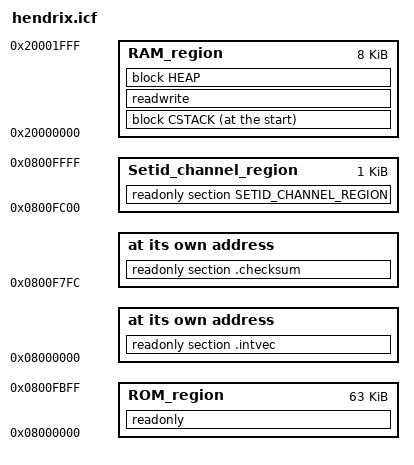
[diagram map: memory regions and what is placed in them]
/*###ICF### Section handled by ICF editor, don't touch! ****/
/*-Editor annotation file-*/
/* IcfEditorFile="$TOOLKIT_DIR$\config\ide\IcfEditor\cortex_v1_0.xml" */
/*-Specials-*/
define symbol __ICFEDIT_intvec_start__    = 0x08000000;
define symbol __USEREDIT_checksum_start__ = 0x0800f7fc;

/*-Memory Regions-*/
define symbol __ICFEDIT_region_ROM_start__ = 0x08000000;
define symbol __ICFEDIT_region_ROM_end__   = 0x0800FBFF;
define symbol __ICFEDIT_region_RAM_start__ = 0x20000000;
define symbol __ICFEDIT_region_RAM_end__   = 0x20001FFF;

/*-2nd ROM region to store SETID_CHANNEL, 1k Byte-*/
define symbol __USEREDIT_region_ROM2_start__ = 0x0800FC00;
define symbol __USEREDIT_region_ROM2_end__   = 0x0800FFFF;


/*-Sizes-*/
define symbol __ICFEDIT_size_cstack__ = 0x800;
define symbol __ICFEDIT_size_heap__   = 0x400;
/**** End of ICF editor section. ###ICF###*/

define memory mem with size = 4G;
define region ROM_region   = mem:[from __ICFEDIT_region_ROM_start__   to __ICFEDIT_region_ROM_end__];
define region RAM_region   = mem:[from __ICFEDIT_region_RAM_start__   to __ICFEDIT_region_RAM_end__];

define region Setid_channel_region  = mem:[from __USEREDIT_region_ROM2_start__ to __USEREDIT_region_ROM2_end__];

define block CSTACK    with alignment = 8, size = __ICFEDIT_size_cstack__   { };
define block HEAP      with alignment = 8, size = __ICFEDIT_size_heap__     { };

initialize by copy { readwrite };
do not initialize  { section .noinit };

place at address mem:__ICFEDIT_intvec_start__ { readonly section .intvec };
place at address mem:__USEREDIT_checksum_start__ { readonly section .checksum };
/*place at address mem:0x8004000 {readonly section IICget_status};//add by richard.tang */

place in ROM_region   { readonly };
/*place in RAM_region   { readwrite,*/
/*                        block CSTACK, block HEAP };*/
place at start of RAM_region {block CSTACK }; /* stack at the start of RAM */
place in RAM_region { readwrite, block HEAP  };



export symbol __ICFEDIT_region_RAM_start__;
export symbol __ICFEDIT_region_RAM_end__;


place in Setid_channel_region  { readonly section SETID_CHANNEL_REGION };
